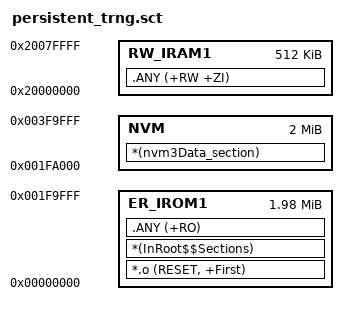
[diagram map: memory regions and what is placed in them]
; *************************************************************
; *** Scatter-Loading Description File generated by uVision ***
; *************************************************************

LR_IROM1 0x00000000 0x00200000  {    ; load region size_region
  ER_IROM1 0x00000000 0x001FA000  {  ; load address = execution address
   *.o (RESET, +First)
   *(InRoot$$Sections)
   .ANY (+RO)
  }
  NVM 0x001FA000 0x00200000 {  ; Fixed placement of NVM3 data
   *(nvm3Data_section)
  }
  RW_IRAM1 0x20000000 0x00080000  {  ; RW data
   .ANY (+RW +ZI)
  }
}

